# RP2350 register map
Vendor: Raspberry Pi; File version: 0.1
CPU: CM33 r1p0, little endian, MPU, FPU, VTOR, 4 interrupt priority bits, 54 interrupts, 8 SAU regions
Registers are 32-bit, read-write, reset 0x0 unless marked. A register's access mark holds for its fields unless they carry their own. Offsets are from the block's base; [hi:lo] are bit positions; {n}, {i} and the like mark numbered series.

## PWM — Simple PWM
Base 0x400A8000
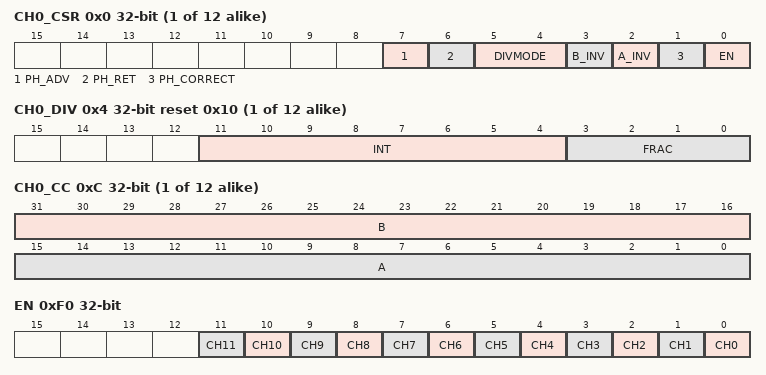
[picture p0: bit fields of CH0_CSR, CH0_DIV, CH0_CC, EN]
{0x0+0x14*i} CH{i}_CSR (i=0..11) — Control and status register
  [7] PH_ADV write-clears — Advance the phase of the counter by 1 count, while it is running. Self-clearing. Write a 1, and poll until low. Counter must be running at less than full speed (div_int + div_frac / 16 > 1)
  [6] PH_RET write-clears — Retard the phase of the counter by 1 count, while it is running. Self-clearing. Write a 1, and poll until low. Counter must be running.
  [5:4] DIVMODE
    0=div (Free-running counting at rate dictated by fractional divider); 1=level (Fractional divider operation is gated by the PWM B pin.); 2=rise (Counter advances with each rising edge of the PWM B pin.); 3=fall (Counter advances with each falling edge of the PWM B pin.)
  [3] B_INV — Invert output B
  [2] A_INV — Invert output A
  [1] PH_CORRECT — 1: Enable phase-correct modulation. 0: Trailing-edge
  [0] EN — Enable the PWM channel.
{0x4+0x14*i} CH{i}_DIV reset 0x10 (i=0..11) — INT and FRAC form a fixed-point fractional number. Counting rate is system clock frequency divided by this number. Fractional division uses simple 1st-order sigma-delta.
  [11:4] INT, [3:0] FRAC
{0x8+0x14*i} CH{i}_CTR (i=0..11) — Direct access to the PWM counter
  [15:0] CH{i}_CTR
{0xC+0x14*i} CH{i}_CC (i=0..11) — Counter compare values
  [31:16] B, [15:0] A
{0x10+0x14*i} CH{i}_TOP reset 0xFFFF (i=0..11) — Counter wrap value
  [15:0] CH{i}_TOP
0xF0 EN — This register aliases the CSR_EN bits for all channels. Writing to this register allows multiple channels to be enabled or disabled simultaneously, so they can run in perfect sync. For each channel, there is only one physical EN register bit, which can be accessed through here or CHx_CSR.
  [n] CH{n} (n=0..11)
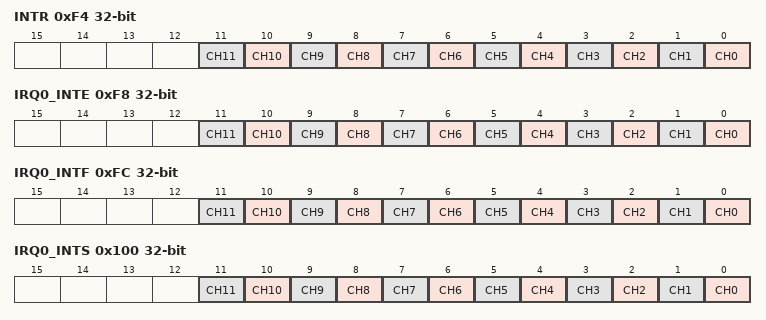
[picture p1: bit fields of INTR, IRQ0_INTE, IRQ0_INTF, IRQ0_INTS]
0xF4 INTR — Raw Interrupts
  [n] CH{n} write-1-clears (n=0..11)
0xF8 IRQ0_INTE — Interrupt Enable for irq0
  [n] CH{n} (n=0..11)
0xFC IRQ0_INTF — Interrupt Force for irq0
  [n] CH{n} (n=0..11)
0x100 IRQ0_INTS ro — Interrupt status after masking & forcing for irq0
  [n] CH{n} (n=0..11)
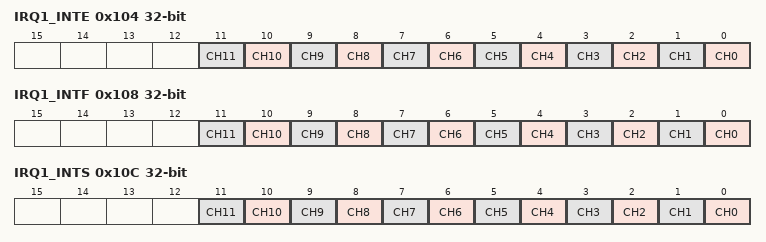
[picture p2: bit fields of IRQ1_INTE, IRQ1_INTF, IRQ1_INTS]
0x104 IRQ1_INTE — Interrupt Enable for irq1
  [n] CH{n} (n=0..11)
0x108 IRQ1_INTF — Interrupt Force for irq1
  [n] CH{n} (n=0..11)
0x10C IRQ1_INTS ro — Interrupt status after masking & forcing for irq1
  [n] CH{n} (n=0..11)

## TIMER0 — Controls time and alarms time is a 64 bit value indicating the time since power-on timeh is the top 32 bits of time & timel is the bottom 32 bits to change time write to timelw before timehw to read time read from timelr before timehr. An alarm is set by setting alarm_enable and writing to the corresponding alarm register. When an alarm is pending, the corresponding alarm_running signal will be high. An alarm can be cancelled before it has finished by clearing the alarm_enable. When an alarm fires, the corresponding alarm_irq is set and alarm_running is cleared. To clear the interrupt write a 1 to the corresponding alarm_irq. The timer can be locked to prevent writing
Base 0x400B0000
Same registers: TIMER1 0x400B8000
0x00 TIMEHW wo read-has-side-effects — Write to bits 63:32 of time always write timelw before timehw
0x04 TIMELW wo read-has-side-effects — Write to bits 31:0 of time writes do not get copied to time until timehw is written
0x08 TIMEHR ro — Read from bits 63:32 of time always read timelr before timehr
0x0C TIMELR ro read-has-side-effects — Read from bits 31:0 of time
{0x10+4i} ALARM{i} (i=0..3) — Arm alarm {i}, and configure the time it will fire. Once armed, the alarm fires when TIMER_ALARM{i} == TIMELR. The alarm will disarm itself once it fires, and can be disarmed early using the ARMED status register.
0x20 ARMED — Indicates the armed/disarmed status of each alarm. A write to the corresponding ALARMx register arms the alarm. Alarms automatically disarm upon firing, but writing ones here will disarm immediately without waiting to fire.
  [3:0] ARMED write-1-clears
0x24 TIMERAWH ro — Raw read from bits 63:32 of time (no side effects)
0x28 TIMERAWL ro — Raw read from bits 31:0 of time (no side effects)
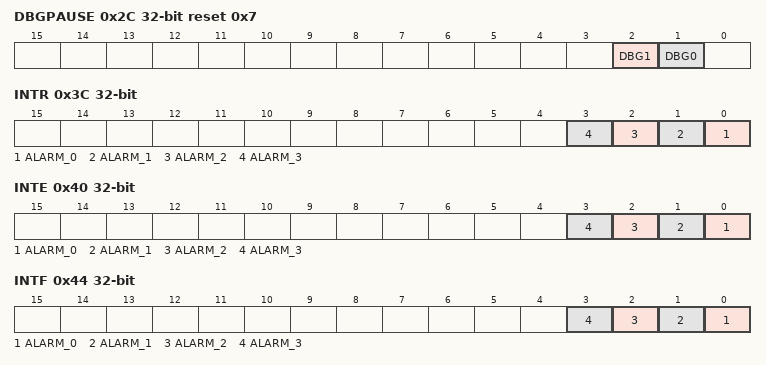
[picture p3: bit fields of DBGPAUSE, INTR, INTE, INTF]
0x2C DBGPAUSE reset 0x7 — Set bits high to enable pause when the corresponding debug ports are active
  [2] DBG1 — Pause when processor 1 is in debug mode
  [1] DBG0 — Pause when processor 0 is in debug mode
0x30 PAUSE — Set high to pause the timer
  [0] PAUSE
0x34 LOCKED — Set locked bit to disable write access to timer. Once set, cannot be cleared (without a reset)
  [0] LOCKED
0x38 SOURCE — Selects the source for the timer. Defaults to the normal tick configured in the ticks block (typically configured to 1 microsecond). Writing to 1 will ignore the tick and count clk_sys cycles instead.
  [0] CLK_SYS
    0=TICK; 1=CLK_SYS
0x3C INTR — Raw Interrupts
  [n] ALARM_{n} write-1-clears (n=0..3)
0x40 INTE — Interrupt Enable
  [n] ALARM_{n} (n=0..3)
0x44 INTF — Interrupt Force
  [n] ALARM_{n} (n=0..3)
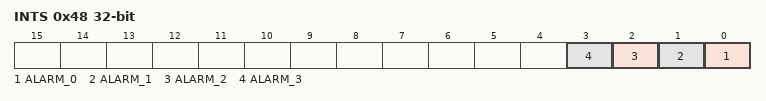
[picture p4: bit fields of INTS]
0x48 INTS ro — Interrupt status after masking & forcing
  [n] ALARM_{n} (n=0..3)
